# MAIN_SEC_MMR_MAIN_SEC_MMR_CFG2_45900000h register map
Vendor: Texas Instruments
Peripheral module from a debugger description file (folder AM275x).
Registers are 32-bit, read-write, reset 0xAA00 unless marked. A register's access mark holds for its fields unless they carry their own. Offsets are as the file gives them; lines under a group give offsets from that group; [hi:lo] are bit positions; {n}, {i} and the like mark numbered series; 'fields as' and 'values as' point back to an identical list; <NAME> marks a mode.

## MAIN_SEC_MMR_CFG2
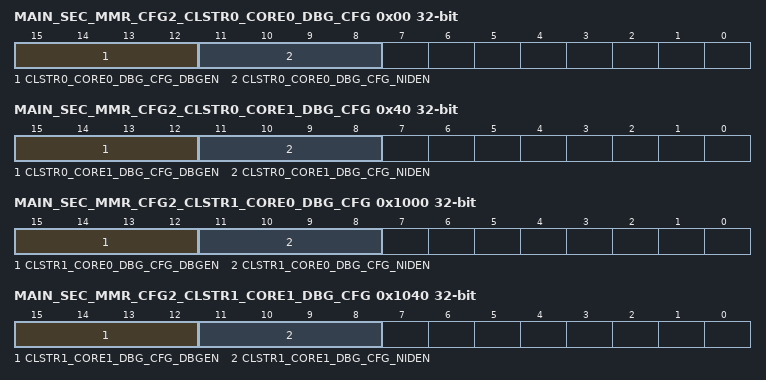
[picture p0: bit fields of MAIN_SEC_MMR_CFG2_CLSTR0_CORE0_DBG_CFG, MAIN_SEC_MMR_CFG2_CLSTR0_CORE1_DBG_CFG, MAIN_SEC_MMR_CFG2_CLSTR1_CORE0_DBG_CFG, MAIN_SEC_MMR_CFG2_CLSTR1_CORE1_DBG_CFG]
0x00 MAIN_SEC_MMR_CFG2_CLSTR0_CORE0_DBG_CFG — Configures debug operation for R5FSS0 Core0
  [15:12] CLSTR0_CORE0_DBG_CFG_DBGEN — Core0 Invasive debug enable. This is a fault tolerant bitfield that must be set 4'hA to enable 4'b1010 - Enabled others - Disabled Reset Source: sys_por_rst_n
  [11:8] CLSTR0_CORE0_DBG_CFG_NIDEN — Core0 Non-invasive debug enable. This is a fault tolerant bitfield that must be set 4'hA to enable 4'b1010 - Enabled others - Disabled Reset Source: sys_por_rst_n
0x40 MAIN_SEC_MMR_CFG2_CLSTR0_CORE1_DBG_CFG — Configures debug operation for R5FSS0 Core1
  [15:12] CLSTR0_CORE1_DBG_CFG_DBGEN — Core1 Invasive debug enable. This is a fault tolerant bitfield that must be set 4'hA to enable 4'b1010 - Enabled others - Disabled Reset Source: sys_por_rst_n
  [11:8] CLSTR0_CORE1_DBG_CFG_NIDEN — Core1 Non-invasive debug enable.This is a fault tolerant bitfield that must be set 4'hA to enable 4'b1010 - Enabled others - Disabled Reset Source: sys_por_rst_n
0x1000 MAIN_SEC_MMR_CFG2_CLSTR1_CORE0_DBG_CFG — Configures debug operation for R5FSS1 Core0
  [15:12] CLSTR1_CORE0_DBG_CFG_DBGEN — Core0 Invasive debug enable. This is a fault tolerant bitfield that must be set 4'hA to enable 4'b1010 - Enabled others - Disabled Reset Source: sys_por_rst_n
  [11:8] CLSTR1_CORE0_DBG_CFG_NIDEN — Core0 Non-invasive debug enable. This is a fault tolerant bitfield that must be set 4'hA to enable 4'b1010 - Enabled others - Disabled Reset Source: sys_por_rst_n
0x1040 MAIN_SEC_MMR_CFG2_CLSTR1_CORE1_DBG_CFG — Configures debug operation for R5FSS1 Core1
  [15:12] CLSTR1_CORE1_DBG_CFG_DBGEN — Core1 Invasive debug enable. This is a fault tolerant bitfield that must be set 4'hA to enable 4'b1010 - Enabled others - Disabled Reset Source: sys_por_rst_n
  [11:8] CLSTR1_CORE1_DBG_CFG_NIDEN — Core1 Non-invasive debug enable.This is a fault tolerant bitfield that must be set 4'hA to enable 4'b1010 - Enabled others - Disabled Reset Source: sys_por_rst_n
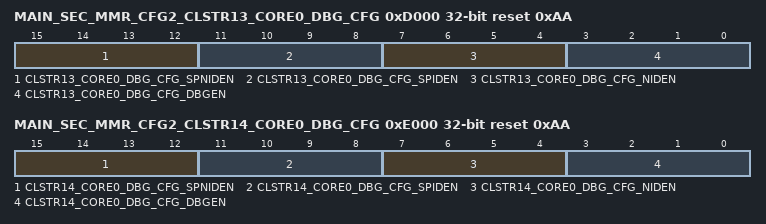
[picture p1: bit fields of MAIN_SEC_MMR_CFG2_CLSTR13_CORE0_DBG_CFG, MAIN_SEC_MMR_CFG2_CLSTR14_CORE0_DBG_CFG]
0xD000 MAIN_SEC_MMR_CFG2_CLSTR13_CORE0_DBG_CFG access per field reset 0xAA — Configures debug operation for C7x 0
  [15:12] CLSTR13_CORE0_DBG_CFG_SPNIDEN ro — Core0 Secure Non-invasive debug enable. 4'b1010 - Enabled others - Disabled Reset Source: sys_por_rst_n
  [11:8] CLSTR13_CORE0_DBG_CFG_SPIDEN ro — Core0 Secure Invasive debug enable. 4'b1010 - Enabled others - Disabled Reset Source: sys_por_rst_n
  [7:4] CLSTR13_CORE0_DBG_CFG_NIDEN rw — Core0 Non-invasive debug enable. This is a fault tolerant bitfield that must be set 4'hA to enable 4'b1010 - Enabled others - Disabled Reset Source: sys_por_rst_n
  [3:0] CLSTR13_CORE0_DBG_CFG_DBGEN rw — Core0 Invasive debug enable. This is a fault tolerant bitfield that must be set 4'hA to enable 4'b1010 - Enabled others - Disabled Reset Source: sys_por_rst_n
0xE000 MAIN_SEC_MMR_CFG2_CLSTR14_CORE0_DBG_CFG access per field reset 0xAA — Configures debug operation for C7x 1
  [15:12] CLSTR14_CORE0_DBG_CFG_SPNIDEN ro — Core0 Secure Non-invasive debug enable. 4'b1010 - Enabled others - Disabled Reset Source: sys_por_rst_n
  [11:8] CLSTR14_CORE0_DBG_CFG_SPIDEN ro — Core0 Secure Invasive debug enable. 4'b1010 - Enabled others - Disabled Reset Source: sys_por_rst_n
  [7:4] CLSTR14_CORE0_DBG_CFG_NIDEN rw — Core0 Non-invasive debug enable. This is a fault tolerant bitfield that must be set 4'hA to enable 4'b1010 - Enabled others - Disabled Reset Source: sys_por_rst_n
  [3:0] CLSTR14_CORE0_DBG_CFG_DBGEN rw — Core0 Invasive debug enable. This is a fault tolerant bitfield that must be set 4'hA to enable 4'b1010 - Enabled others - Disabled Reset Source: sys_por_rst_n
